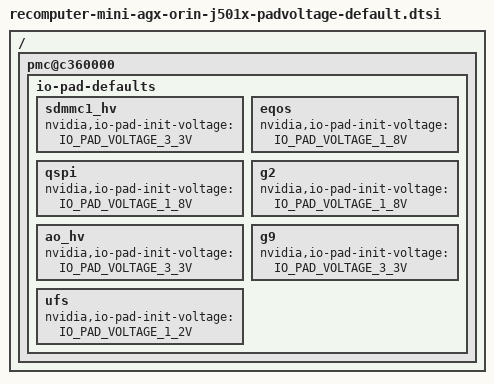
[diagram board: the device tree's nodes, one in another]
/*This dtsi file was generated by recomputer-mini-agx-orin-j501x.xlsm Revision: 1 */
/*
 * Copyright (c) 2021, NVIDIA CORPORATION.  All rights reserved.
 *
 * This program is free software; you can redistribute it and/or modify
 * it under the terms of the GNU General Public License as published by
 * the Free Software Foundation; either version 2 of the License, or
 * (at your option) any later version.
 *
 * This program is distributed in the hope that it will be useful, but WITHOUT
 * ANY WARRANTY; without even the implied warranty of MERCHANTABILITY or
 * FITNESS FOR A PARTICULAR PURPOSE.  See the GNU General Public License for
 * more details.
 */

		#define IO_PAD_VOLTAGE_1_2V 1200000
		#define IO_PAD_VOLTAGE_1_8V 1800000
		#define IO_PAD_VOLTAGE_3_3V 3300000
/dts-v1/;
/ {
	pmc@c360000 {
		io-pad-defaults {
			sdmmc1_hv {
				nvidia,io-pad-init-voltage = <IO_PAD_VOLTAGE_3_3V>;
			};

			eqos {
				nvidia,io-pad-init-voltage = <IO_PAD_VOLTAGE_1_8V>;
			};

			qspi {
				nvidia,io-pad-init-voltage = <IO_PAD_VOLTAGE_1_8V>;
			};

			g2 {
				nvidia,io-pad-init-voltage = <IO_PAD_VOLTAGE_1_8V>;
			};

			ao_hv {
				nvidia,io-pad-init-voltage = <IO_PAD_VOLTAGE_3_3V>;
			};

			g9 {
				nvidia,io-pad-init-voltage = <IO_PAD_VOLTAGE_3_3V>;
			};

			ufs {
				nvidia,io-pad-init-voltage = <IO_PAD_VOLTAGE_1_2V>;
			};

		};
	};
};
